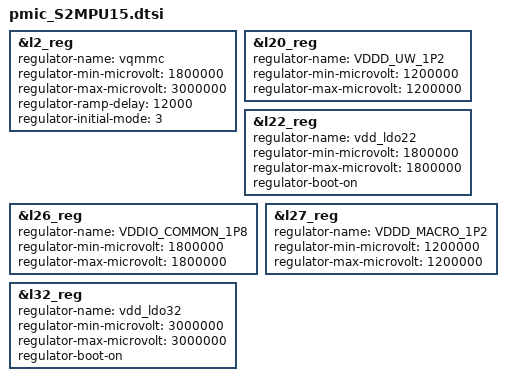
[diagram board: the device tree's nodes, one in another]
#if 0 && 0
&l1_reg {
	regulator-name = "vdd_ldo1";
	regulator-min-microvolt = <0>;
	regulator-max-microvolt = <0>;
	 
	
};
#endif

#if 1800000 && 3000000
&l2_reg {
	regulator-name = "vqmmc";
	regulator-min-microvolt = <1800000>;
	regulator-max-microvolt = <3000000>;
	regulator-ramp-delay = <12000>;regulator-initial-mode = <3>;
	/delete-property/ regulator-always-on;
};
#endif

#if 0 && 0
&l3_reg {
	regulator-name = "vdd_ldo3";
	regulator-min-microvolt = <0>;
	regulator-max-microvolt = <0>;
	 
	
};
#endif

#if 0 && 0
&l4_reg {
	regulator-name = "vdd_ldo4";
	regulator-min-microvolt = <0>;
	regulator-max-microvolt = <0>;
	 
	
};
#endif

#if 0 && 0
&l5_reg {
	regulator-name = "vdd_ldo5";
	regulator-min-microvolt = <0>;
	regulator-max-microvolt = <0>;
	 
	
};
#endif

#if 0 && 0
&l6_reg {
	regulator-name = "vdd_ldo6";
	regulator-min-microvolt = <0>;
	regulator-max-microvolt = <0>;
	 
	
};
#endif

#if 0 && 0
&l7_reg {
	regulator-name = "vdd_ldo7";
	regulator-min-microvolt = <0>;
	regulator-max-microvolt = <0>;
	 
	
};
#endif

#if 0 && 0
&l8_reg {
	regulator-name = "vdd_ldo8";
	regulator-min-microvolt = <0>;
	regulator-max-microvolt = <0>;
	 
	
};
#endif

#if 0 && 0
&l9_reg {
	regulator-name = "vdd_ldo9";
	regulator-min-microvolt = <0>;
	regulator-max-microvolt = <0>;
	 
	
};
#endif

#if 0 && 0
&l10_reg {
	regulator-name = "vdd_ldo10";
	regulator-min-microvolt = <0>;
	regulator-max-microvolt = <0>;
	 
	
};
#endif

#if 0 && 0
&l11_reg {
	regulator-name = "vdd_ldo11";
	regulator-min-microvolt = <0>;
	regulator-max-microvolt = <0>;
	 
	
};
#endif

#if 0 && 0
&l12_reg {
	regulator-name = "vdd_ldo12";
	regulator-min-microvolt = <0>;
	regulator-max-microvolt = <0>;
	 
	
};
#endif

#if 0 && 0
&l13_reg {
	regulator-name = "vdd_ldo13";
	regulator-min-microvolt = <0>;
	regulator-max-microvolt = <0>;
	 
	
};
#endif

#if 0 && 0
&l14_reg {
	regulator-name = "vdd_ldo14";
	regulator-min-microvolt = <0>;
	regulator-max-microvolt = <0>;
	 
	
};
#endif

#if 0 && 0
&l15_reg {
	regulator-name = "vdd_ldo15";
	regulator-min-microvolt = <0>;
	regulator-max-microvolt = <0>;
	 
	
};
#endif

#if 0 && 0
&l16_reg {
	regulator-name = "vdd_ldo16";
	regulator-min-microvolt = <0>;
	regulator-max-microvolt = <0>;
	 
	
};
#endif

#if 0 && 0
&l17_reg {
	regulator-name = "vdd_ldo17";
	regulator-min-microvolt = <0>;
	regulator-max-microvolt = <0>;
	 
	
};
#endif

#if 0 && 0
&l18_reg {
	regulator-name = "vdd_ldo18";
	regulator-min-microvolt = <0>;
	regulator-max-microvolt = <0>;
	 
	
};
#endif

#if 0 && 0
&l19_reg {
	regulator-name = "vdd_ldo19";
	regulator-min-microvolt = <0>;
	regulator-max-microvolt = <0>;
	 
	
};
#endif

#if 1200000 && 1200000
&l20_reg {
	regulator-name = "VDDD_UW_1P2";
	regulator-min-microvolt = <1200000>;
	regulator-max-microvolt = <1200000>;
	 
	
};
#endif

#if 0 && 0
&l21_reg {
	regulator-name = "vdd_ldo21";
	regulator-min-microvolt = <0>;
	regulator-max-microvolt = <0>;
	 
	
};
#endif

#if 1800000 && 1800000
&l22_reg {
	regulator-name = "vdd_ldo22";
	regulator-min-microvolt = <1800000>;
	regulator-max-microvolt = <1800000>;
	 
	regulator-boot-on;
};
#endif

#if 0 && 0
&l23_reg {
	regulator-name = "vdd_ldo23";
	regulator-min-microvolt = <0>;
	regulator-max-microvolt = <0>;
	 
	
};
#endif

#if 0 && 0
&l24_reg {
	regulator-name = "vdd_ldo24";
	regulator-min-microvolt = <0>;
	regulator-max-microvolt = <0>;
	 
	
};
#endif

#if 0 && 0
&l25_reg {
	regulator-name = "vdd_ldo25";
	regulator-min-microvolt = <0>;
	regulator-max-microvolt = <0>;
	 
	
};
#endif

#if 1800000 && 1800000
&l26_reg {
	regulator-name = "VDDIO_COMMON_1P8";
	regulator-min-microvolt = <1800000>;
	regulator-max-microvolt = <1800000>;
	 
	
};
#endif

#if 1200000 && 1200000
&l27_reg {
	regulator-name = "VDDD_MACRO_1P2";
	regulator-min-microvolt = <1200000>;
	regulator-max-microvolt = <1200000>;
	 
	
};
#endif

#if 0 && 0
&l28_reg {
	regulator-name = "vdd_ldo28";
	regulator-min-microvolt = <0>;
	regulator-max-microvolt = <0>;
	 
	
};
#endif

#if 0 && 0
&l29_reg {
	regulator-name = "vdd_ldo29";
	regulator-min-microvolt = <0>;
	regulator-max-microvolt = <0>;
	 
	
};
#endif

#if 0 && 0
&l30_reg {
	regulator-name = "vdd_ldo30";
	regulator-min-microvolt = <0>;
	regulator-max-microvolt = <0>;
	 
	
};
#endif

#if 0 && 0
&l31_reg {
	regulator-name = "vdd_ldo31";
	regulator-min-microvolt = <0>;
	regulator-max-microvolt = <0>;
	 
	
};
#endif

#if 3000000 && 3000000
&l32_reg {
	regulator-name = "vdd_ldo32";
	regulator-min-microvolt = <3000000>;
	regulator-max-microvolt = <3000000>;
	 
	regulator-boot-on;/delete-property/ regulator-always-on;
};
#endif

#if 0 && 0
&l33_reg {
	regulator-name = "vdd_ldo33";
	regulator-min-microvolt = <0>;
	regulator-max-microvolt = <0>;
	 
	
};
#endif

#if 0 && 0
&l34_reg {
	regulator-name = "vdd_ldo34";
	regulator-min-microvolt = <0>;
	regulator-max-microvolt = <0>;
	 
	
};
#endif

#if 0 && 0
&l35_reg {
	regulator-name = "vdd_ldo35";
	regulator-min-microvolt = <0>;
	regulator-max-microvolt = <0>;
	 
	
};
#endif


/* /home/dpi/qb5_8815/workspace/P4_1716/android/kernel/kmodule/pmic/slsi/S2MPU15/dts/pmic_S2MPU15.a55x.dtsi */
/delete-node/ &l19_reg;
/delete-node/ &l21_reg;
